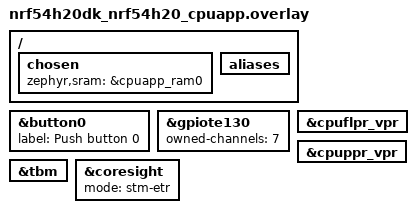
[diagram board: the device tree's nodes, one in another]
/*
 * Copyright (c) 2024 Nordic Semiconductor ASA
 *
 * SPDX-License-Identifier: LicenseRef-Nordic-5-Clause
 */

 #include "app_aliases_common.dtsi"

/ {
	chosen {
		zephyr,sram = &cpuapp_ram0;
	};

	aliases {
		/delete-property/ led1;
		/delete-property/ sw1;
	};
};

/delete-node/ &button1;
/delete-node/ &led1;

&button0 {
	label = "Push button 0";
};

&gpiote130 {
	/* Select the only free channel. */
	owned-channels = <7>;
	status = "okay";
};

/* DTS nodes required to run the cpuflpr target. */
&cpuflpr_vpr {
	status = "okay";
};

/* DTS nodes required to run the cpuppr target. */
&cpuppr_vpr {
	status = "okay";
};

/* DTS nodes required for the STM standalone logging, imported from the nordic-log-stm snippet. */
&tbm {
	status = "okay";
};

&coresight {
	status = "okay";
	mode = "stm-etr";
};
